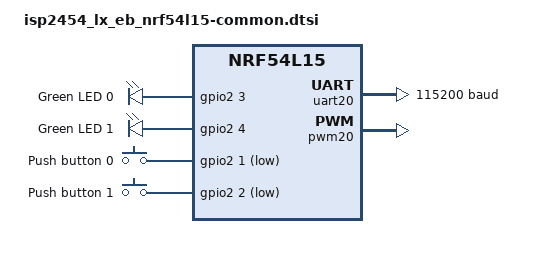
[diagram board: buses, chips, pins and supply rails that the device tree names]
/*
 * Copyright (c) 2024 Nordic Semiconductor ASA
 *
 * SPDX-License-Identifier: Apache-2.0
 */

#include "isp2454_lx_eb_nrf54l15-pinctrl.dtsi"

/ {
	leds {
		compatible = "gpio-leds";
		led0: led_0 {
			gpios = <&gpio2 3 GPIO_ACTIVE_HIGH>;
			label = "Green LED 0";
		};
		led1: led_1 {
			gpios = <&gpio2 4 GPIO_ACTIVE_HIGH>;
			label = "Green LED 1";
		};
	};

	buttons {
		compatible = "gpio-keys";
		button0: button_0 {
			gpios = <&gpio2 1 (GPIO_PULL_UP | GPIO_ACTIVE_LOW)>;
			label = "Push button 0";
			zephyr,code = <INPUT_KEY_0>;
		};
		button1: button_1 {
			gpios = <&gpio2 2 (GPIO_PULL_UP | GPIO_ACTIVE_LOW)>;
			label = "Push button 1";
			zephyr,code = <INPUT_KEY_1>;
		};
	};

	aliases {
		led0 = &led0;
		led1 = &led1;
		sw0 = &button0;
		sw1 = &button1;
		watchdog0 = &wdt31;
	};
};

&uart20 {
	current-speed = <115200>;
	pinctrl-0 = <&uart20_default>;
	pinctrl-1 = <&uart20_sleep>;
	pinctrl-names = "default", "sleep";
};

&pwm20 {
	status = "okay";
	pinctrl-0 = <&pwm20_default>;
	pinctrl-1 = <&pwm20_sleep>;
	pinctrl-names = "default", "sleep";
};
